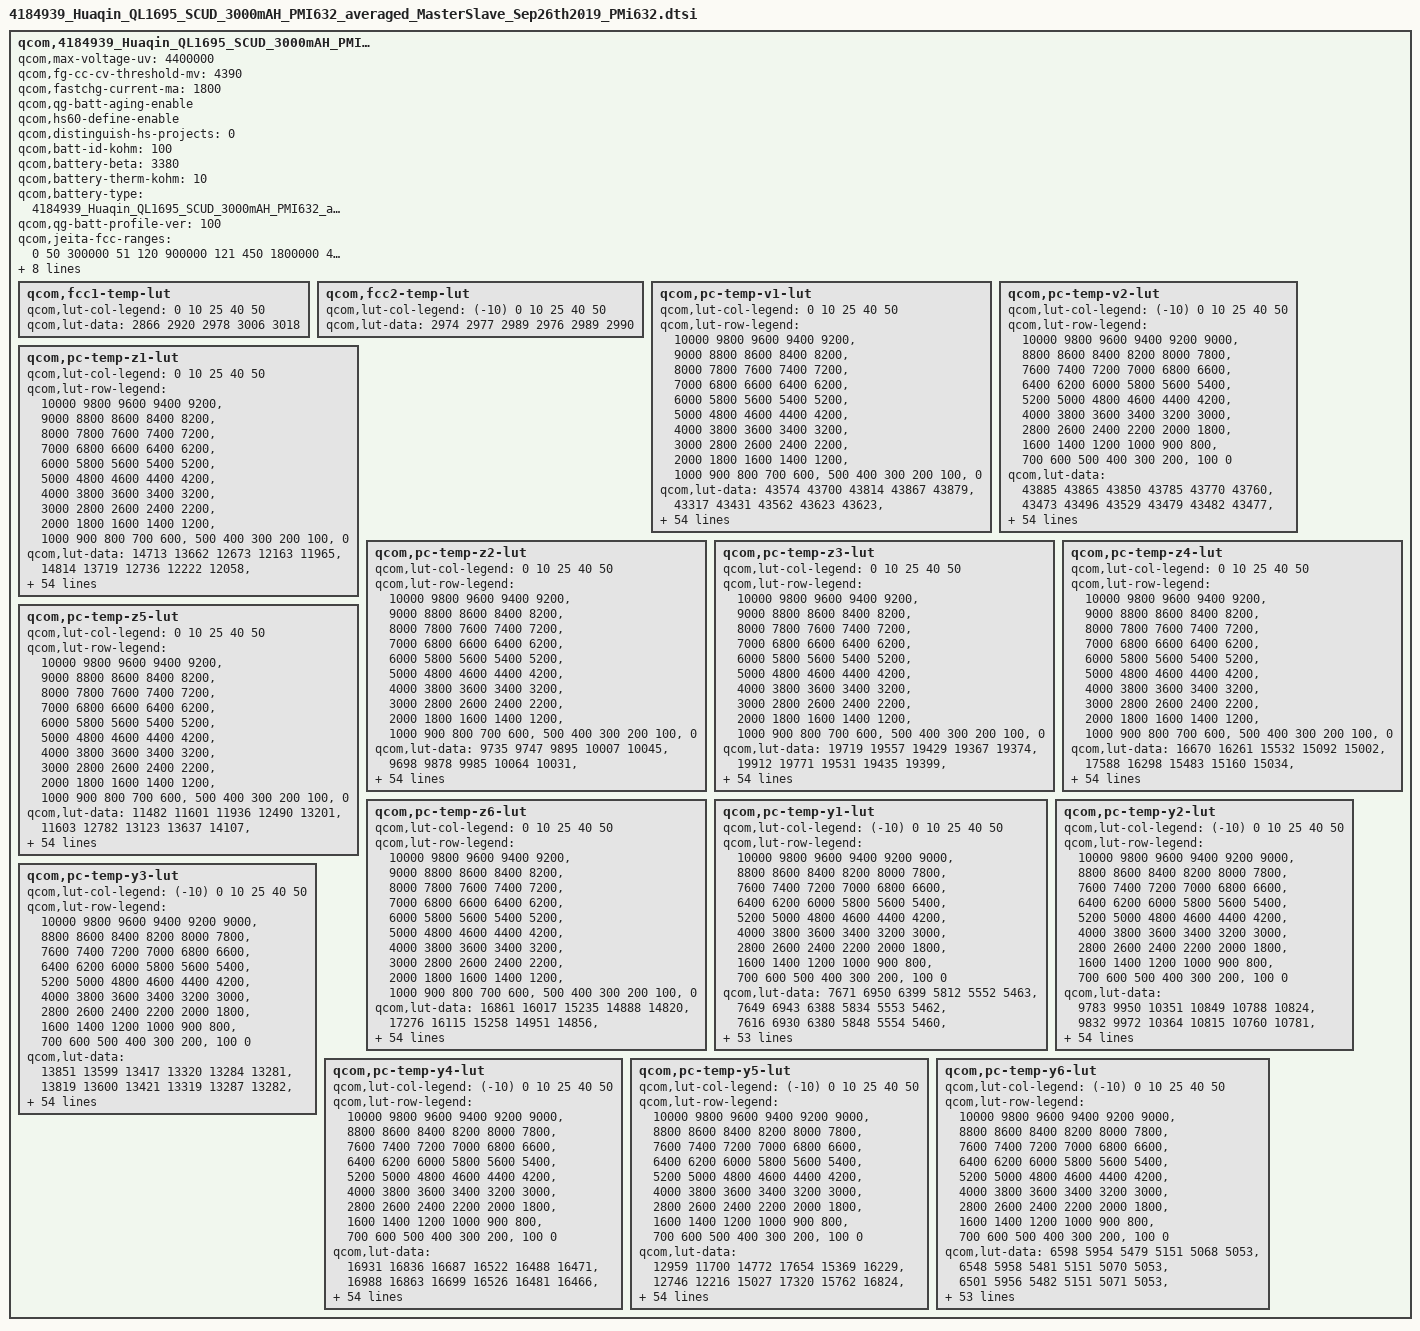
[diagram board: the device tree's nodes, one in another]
qcom,4184939_Huaqin_QL1695_SCUD_3000mAH_PMI632 {
    /* 4184939_Huaqin_QL1695_SCUD_3000mAH_PMI632_averaged_MasterSlave_Sep26th2019 */
    qcom,max-voltage-uv = <4400000>;
    qcom,fg-cc-cv-threshold-mv = <4390>;
    /* HS60 add for ZQL1693-60 Encrease FCC to 1800mA to trigger TA(5V/1.55A) more ICL by gaochao at 2019/11/05 start */
    qcom,fastchg-current-ma = <1800>;
    /* HS60 add for ZQL1693-60 Encrease FCC to 1800mA to trigger TA(5V/1.55A) more ICL by gaochao at 2019/11/05 end */
	/* HS60 add for SR-ZQL1695-01-357 Import battery aging by gaochao at 2019/08/29 start */
	qcom,qg-batt-aging-enable;
	/* HS60 add for SR-ZQL1695-01-357 Import battery aging by gaochao at 2019/08/29 end */
    /* HS70 add for HS70-135 Distinguish HS60 and HS70 charging by gaochao at 2019/10/03 start */
    qcom,hs60-define-enable;
    /* HS70 add for HS70-135 Distinguish HS60 and HS70 charging by gaochao at 2019/10/03 end */
	/* HS50 add for SR-QL3095-01-67 Distinguish HS60, HS70 and HS50 charging by wenyaqi at 2020/8/3 start */
	qcom,distinguish-hs-projects = <0>;
	/* HS50 add for SR-QL3095-01-67 Distinguish HS60, HS70 and HS50 charging by wenyaqi at 2020/8/3 end */
    qcom,batt-id-kohm = <100>;
    qcom,battery-beta = <3380>;
    qcom,battery-therm-kohm = <10>;
    qcom,battery-type = "4184939_Huaqin_QL1695_SCUD_3000mAH_PMI632_averaged_MasterSlave_Sep26th2019";
    qcom,qg-batt-profile-ver = <100>;

	/*HS60 add for ZQL1693-50 by wangzikang at 2019/09/26 start*/
	/*HS60 add for ZQL1693-58 by wangzikang at 2019/10/18 start*/
	/* HS60 add for ZQL1693-60 Encrease FCC to 1800mA to trigger TA(5V/1.55A) more ICL by gaochao at 2019/11/05 start */
	qcom,jeita-fcc-ranges = <0   50   300000
				 51   120   900000
				 121 450  1800000
				 451 500  1800000>;
	/* HS60 add for ZQL1693-60 Encrease FCC to 1800mA to trigger TA(5V/1.55A) more ICL by gaochao at 2019/11/05 end */
	/*HS60 add for ZQL1693-58 by wangzikang at 2019/10/18 end*/
	qcom,jeita-fv-ranges =  <0   50  4400000
				 51   120  4400000
				 121 450  4400000
				 451 500  4200000>;
	/*HS60 add for ZQL1693-50 by wangzikang at 2019/09/26 end*/

	/* HS60 add for SR-ZQL1695-01-357 Import battery aging by gaochao at 2019/08/29 start */
	qcom,vfloat-ranges = <0 299 4400000
	                      300 399 4380000
                              400 699 4360000
                              700 999 4340000
                              1000 9999 4290000>;

	qcom,vbat-rechg-ranges = <0 299 4330000
                                  300 399 4310000
                                  400 699 4290000
                                  700 999 4270000
                                  1000 9999 4220000>;
	/* HS60 add for SR-ZQL1695-01-357 Import battery aging by gaochao at 2019/08/29 end */

	/* COOL = 15 DegC, WARM = 45 DegC */
	qcom,jeita-soft-thresholds = <0x2554 0xFDC>;
	/* COLD = 0 DegC, HOT = 55 DegC */
	/*HS60 add for USER REQUEIREMENT by wangzikang at 2019/09/26 start*/
	qcom,jeita-hard-thresholds = <0x36B9 0xDBF>;//0xBEF -->0xDBF
	/*HS60 add for USER REQUEIREMENT by wangzikang at 2019/09/26 end*/

	qcom,fcc1-temp-lut {
		qcom,lut-col-legend = <0 10 25 40 50>;
		qcom,lut-data = <2866 2920 2978 3006 3018>;
	};

	qcom,fcc2-temp-lut {
		qcom,lut-col-legend = <(-10) 0 10 25 40 50>;
		qcom,lut-data = <2974 2977 2989 2976 2989 2990>;
	};

	qcom,pc-temp-v1-lut {
		qcom,lut-col-legend = <0 10 25 40 50>;
		qcom,lut-row-legend = <10000 9800 9600 9400 9200>,
			<9000 8800 8600 8400 8200>,
			<8000 7800 7600 7400 7200>,
			<7000 6800 6600 6400 6200>,
			<6000 5800 5600 5400 5200>,
			<5000 4800 4600 4400 4200>,
			<4000 3800 3600 3400 3200>,
			<3000 2800 2600 2400 2200>,
			<2000 1800 1600 1400 1200>,
			<1000 900 800 700 600>,
			<500 400 300 200 100>,
			<0>;
		qcom,lut-data = <43574 43700 43814 43867 43879>,
			<43317 43431 43562 43623 43623>,
			<43056 43180 43314 43377 43379>,
			<42805 42941 43072 43135 43142>,
			<42568 42706 42833 42898 42910>,
			<42340 42471 42595 42661 42679>,
			<42114 42239 42359 42428 42447>,
			<41891 42010 42125 42196 42213>,
			<41675 41785 41896 41966 41982>,
			<41468 41566 41669 41735 41755>,
			<41268 41356 41447 41507 41529>,
			<41068 41153 41231 41287 41307>,
			<40870 40953 41019 41070 41088>,
			<40669 40761 40815 40862 40877>,
			<40449 40565 40614 40658 40672>,
			<40207 40350 40421 40462 40475>,
			<40001 40132 40230 40274 40284>,
			<39853 39956 40049 40093 40102>,
			<39728 39820 39886 39922 39928>,
			<39602 39690 39738 39769 39772>,
			<39474 39550 39581 39607 39608>,
			<39348 39404 39416 39403 39401>,
			<39225 39240 39238 39173 39165>,
			<39103 39029 39020 38976 38970>,
			<38983 38819 38766 38805 38814>,
			<38865 38666 38600 38664 38683>,
			<38749 38537 38523 38561 38574>,
			<38636 38445 38464 38476 38480>,
			<38520 38382 38402 38394 38390>,
			<38426 38335 38341 38313 38300>,
			<38364 38294 38284 38238 38218>,
			<38314 38261 38227 38169 38147>,
			<38275 38229 38173 38107 38084>,
			<38244 38198 38124 38052 38026>,
			<38217 38168 38081 38005 37974>,
			<38188 38137 38041 37960 37923>,
			<38160 38108 38006 37913 37867>,
			<38123 38071 37968 37865 37808>,
			<38071 38012 37908 37801 37735>,
			<38000 37924 37816 37715 37647>,
			<37909 37824 37712 37615 37547>,
			<37778 37706 37603 37504 37435>,
			<37631 37567 37475 37377 37306>,
			<37466 37395 37308 37216 37145>,
			<37317 37251 37158 37070 37002>,
			<37223 37155 37062 36976 36914>,
			<37191 37130 37039 36952 36894>,
			<37161 37104 37019 36938 36878>,
			<37136 37080 37006 36919 36859>,
			<37092 37037 36961 36871 36803>,
			<36898 36828 36741 36624 36526>,
			<36445 36384 36307 36180 36085>,
			<35868 35808 35734 35603 35506>,
			<35084 35020 34952 34816 34714>,
			<33838 33777 33735 33556 33483>,
			<30000 30000 30000 30000 30000>;
	};

	qcom,pc-temp-v2-lut {
		qcom,lut-col-legend = <(-10) 0 10 25 40 50>;
		qcom,lut-row-legend = <10000 9800 9600 9400 9200 9000>,
			<8800 8600 8400 8200 8000 7800>,
			<7600 7400 7200 7000 6800 6600>,
			<6400 6200 6000 5800 5600 5400>,
			<5200 5000 4800 4600 4400 4200>,
			<4000 3800 3600 3400 3200 3000>,
			<2800 2600 2400 2200 2000 1800>,
			<1600 1400 1200 1000 900 800>,
			<700 600 500 400 300 200>,
			<100 0>;
		qcom,lut-data = <43885 43865 43850 43785 43770 43760>,
			<43473 43496 43529 43479 43482 43477>,
			<43106 43162 43231 43193 43211 43209>,
			<42794 42870 42957 42931 42956 42957>,
			<42525 42615 42708 42690 42719 42721>,
			<42282 42372 42466 42456 42487 42490>,
			<42064 42124 42224 42222 42254 42257>,
			<41859 41882 41986 41991 42022 42026>,
			<41624 41647 41756 41764 41794 41798>,
			<41341 41412 41531 41540 41568 41573>,
			<41103 41198 41313 41320 41346 41350>,
			<40973 41030 41106 41107 41130 41132>,
			<40870 40878 40907 40897 40917 40918>,
			<40674 40681 40714 40692 40712 40712>,
			<40245 40416 40529 40486 40509 40512>,
			<39841 40143 40334 40290 40315 40320>,
			<39631 39895 40108 40115 40130 40133>,
			<39473 39658 39868 39950 39952 39953>,
			<39312 39452 39647 39784 39785 39783>,
			<39150 39274 39439 39620 39635 39627>,
			<38988 39107 39242 39443 39469 39458>,
			<38816 38943 39052 39220 39248 39244>,
			<38642 38785 38873 38974 39003 39013>,
			<38495 38628 38714 38780 38810 38824>,
			<38373 38464 38573 38633 38654 38666>,
			<38268 38318 38447 38507 38522 38530>,
			<38184 38207 38335 38393 38411 38417>,
			<38113 38113 38233 38292 38315 38319>,
			<38048 38043 38131 38200 38226 38228>,
			<37988 37989 38024 38117 38145 38145>,
			<37931 37944 37940 38042 38070 38069>,
			<37872 37899 37887 37973 37999 38000>,
			<37813 37857 37847 37912 37933 37936>,
			<37753 37814 37809 37855 37867 37868>,
			<37692 37770 37777 37804 37803 37801>,
			<37631 37724 37743 37754 37734 37725>,
			<37570 37674 37706 37697 37651 37626>,
			<37509 37620 37666 37635 37559 37513>,
			<37448 37559 37614 37568 37474 37417>,
			<37388 37490 37546 37497 37397 37338>,
			<37329 37411 37462 37416 37316 37256>,
			<37272 37313 37349 37317 37218 37159>,
			<37216 37198 37214 37195 37105 37048>,
			<37153 37095 37074 37051 36966 36911>,
			<37083 37002 36948 36919 36852 36804>,
			<36987 36916 36863 36852 36801 36757>,
			<36924 36877 36832 36837 36789 36744>,
			<36859 36837 36803 36818 36773 36729>,
			<36780 36796 36761 36791 36744 36700>,
			<36666 36720 36683 36725 36654 36598>,
			<36461 36516 36472 36494 36341 36271>,
			<36082 36089 36032 36027 35843 35770>,
			<35495 35465 35405 35417 35201 35119>,
			<34623 34590 34539 34597 34325 34250>,
			<33196 33262 33270 33322 32996 32924>,
			<28548 27862 27939 28567 27880 28103>;
	};

	qcom,pc-temp-z1-lut {
		qcom,lut-col-legend = <0 10 25 40 50>;
		qcom,lut-row-legend = <10000 9800 9600 9400 9200>,
			<9000 8800 8600 8400 8200>,
			<8000 7800 7600 7400 7200>,
			<7000 6800 6600 6400 6200>,
			<6000 5800 5600 5400 5200>,
			<5000 4800 4600 4400 4200>,
			<4000 3800 3600 3400 3200>,
			<3000 2800 2600 2400 2200>,
			<2000 1800 1600 1400 1200>,
			<1000 900 800 700 600>,
			<500 400 300 200 100>,
			<0>;
		qcom,lut-data = <14713 13662 12673 12163 11965>,
			<14814 13719 12736 12222 12058>,
			<14837 13710 12765 12244 12079>,
			<14842 13676 12757 12242 12081>,
			<14832 13653 12747 12235 12080>,
			<14812 13641 12735 12228 12078>,
			<14796 13632 12717 12223 12077>,
			<14778 13621 12698 12219 12077>,
			<14766 13599 12683 12216 12077>,
			<14754 13587 12671 12214 12075>,
			<14731 13593 12667 12212 12074>,
			<14710 13602 12670 12212 12075>,
			<14666 13595 12672 12211 12075>,
			<14612 13547 12670 12210 12076>,
			<14580 13511 12663 12210 12077>,
			<14554 13507 12660 12210 12078>,
			<14526 13505 12662 12211 12079>,
			<14480 13506 12666 12213 12080>,
			<14434 13519 12671 12215 12080>,
			<14423 13529 12679 12217 12082>,
			<14431 13530 12684 12220 12084>,
			<14446 13531 12688 12221 12085>,
			<14477 13535 12692 12223 12086>,
			<14530 13545 12695 12225 12088>,
			<14553 13555 12699 12227 12091>,
			<14524 13554 12704 12230 12094>,
			<14486 13551 12712 12235 12098>,
			<14483 13549 12719 12242 12103>,
			<14501 13557 12724 12247 12108>,
			<14517 13568 12727 12252 12113>,
			<14524 13574 12732 12257 12118>,
			<14530 13577 12741 12263 12122>,
			<14534 13581 12752 12269 12126>,
			<14527 13598 12760 12275 12130>,
			<14520 13625 12765 12282 12135>,
			<14528 13642 12771 12288 12139>,
			<14549 13652 12778 12292 12143>,
			<14563 13662 12786 12297 12146>,
			<14580 13674 12793 12302 12150>,
			<14600 13687 12801 12308 12154>,
			<14602 13695 12809 12314 12158>,
			<14594 13701 12825 12320 12162>,
			<14599 13702 12836 12326 12166>,
			<14627 13688 12838 12331 12170>,
			<14896 13713 12859 12338 12174>,
			<14641 13727 12865 12344 12176>,
			<14631 13714 12861 12346 12177>,
			<14608 13728 12858 12346 12179>,
			<14659 13689 12864 12348 12182>,
			<14623 13745 12882 12356 12185>,
			<14644 13777 12879 12365 12193>,
			<14726 13752 12908 12375 12203>,
			<14712 13783 12914 12395 12217>,
			<14712 13859 12978 12417 12236>,
			<14712 13859 12978 12417 12236>,
			<14712 13859 12978 12417 12236>;
	};

	qcom,pc-temp-z2-lut {
		qcom,lut-col-legend = <0 10 25 40 50>;
		qcom,lut-row-legend = <10000 9800 9600 9400 9200>,
			<9000 8800 8600 8400 8200>,
			<8000 7800 7600 7400 7200>,
			<7000 6800 6600 6400 6200>,
			<6000 5800 5600 5400 5200>,
			<5000 4800 4600 4400 4200>,
			<4000 3800 3600 3400 3200>,
			<3000 2800 2600 2400 2200>,
			<2000 1800 1600 1400 1200>,
			<1000 900 800 700 600>,
			<500 400 300 200 100>,
			<0>;
		qcom,lut-data = <9735 9747 9895 10007 10045>,
			<9698 9878 9985 10064 10031>,
			<9781 9879 10030 10125 10123>,
			<9834 9855 10018 10139 10165>,
			<9846 9834 9984 10113 10116>,
			<9853 9819 9955 10078 10057>,
			<9853 9808 9931 10045 10044>,
			<9845 9806 9913 10010 10040>,
			<9837 9805 9908 10001 10032>,
			<9831 9805 9907 10017 9990>,
			<9825 9798 9908 10031 9942>,
			<9818 9790 9919 10029 9924>,
			<9803 9788 9933 10021 9912>,
			<9786 9791 9943 10014 9914>,
			<9772 9794 9953 10006 9935>,
			<9758 9797 9963 10000 9958>,
			<9751 9802 9974 9994 9968>,
			<9755 9810 9984 9987 9976>,
			<9762 9828 9990 9990 9984>,
			<9763 9848 9996 9996 9998>,
			<9753 9862 10004 10006 10021>,
			<9743 9874 10024 10081 10103>,
			<9740 9885 10042 10217 10247>,
			<9738 9898 10041 10241 10281>,
			<9738 9907 10029 10100 10145>,
			<9742 9906 10018 9981 10025>,
			<9751 9901 10006 9993 10048>,
			<9759 9898 9997 10032 10110>,
			<9771 9903 10007 10075 10138>,
			<9780 9910 10045 10134 10144>,
			<9784 9913 10068 10173 10143>,
			<9787 9915 10072 10158 10086>,
			<9790 9917 10073 10124 9980>,
			<9795 9920 10072 10107 9951>,
			<9801 9925 10068 10099 9957>,
			<9808 9930 10068 10095 9968>,
			<9817 9933 10073 10102 10000>,
			<9827 9938 10081 10119 10056>,
			<9840 9947 10093 10140 10094>,
			<9854 9960 10116 10169 10123>,
			<9865 9967 10131 10187 10140>,
			<9875 9969 10135 10181 10143>,
			<9889 9971 10138 10172 10143>,
			<9916 9982 10139 10177 10147>,
			<10099 10081 10176 10170 10151>,
			<10227 10116 10181 10155 10111>,
			<10267 10148 10181 10137 10148>,
			<10264 10169 10168 10166 10136>,
			<10112 10217 10173 10179 10142>,
			<9839 10250 10189 10237 10292>,
			<9856 10244 10308 10258 10078>,
			<10139 10252 10344 10151 9981>,
			<9997 10225 10324 10074 9930>,
			<9839 10155 10292 10002 9887>,
			<9839 10155 10292 10002 9887>,
			<9839 10155 10292 10002 9887>;
	};

	qcom,pc-temp-z3-lut {
		qcom,lut-col-legend = <0 10 25 40 50>;
		qcom,lut-row-legend = <10000 9800 9600 9400 9200>,
			<9000 8800 8600 8400 8200>,
			<8000 7800 7600 7400 7200>,
			<7000 6800 6600 6400 6200>,
			<6000 5800 5600 5400 5200>,
			<5000 4800 4600 4400 4200>,
			<4000 3800 3600 3400 3200>,
			<3000 2800 2600 2400 2200>,
			<2000 1800 1600 1400 1200>,
			<1000 900 800 700 600>,
			<500 400 300 200 100>,
			<0>;
		qcom,lut-data = <19719 19557 19429 19367 19374>,
			<19912 19771 19531 19435 19399>,
			<20028 19829 19593 19467 19433>,
			<20069 19859 19611 19485 19451>,
			<19993 19866 19621 19500 19455>,
			<19881 19862 19625 19508 19457>,
			<19851 19856 19624 19504 19457>,
			<19846 19851 19620 19494 19453>,
			<19845 19848 19610 19485 19447>,
			<19848 19844 19592 19478 19435>,
			<19856 19832 19576 19470 19422>,
			<19862 19813 19562 19459 19414>,
			<19864 19790 19550 19445 19409>,
			<19866 19757 19542 19434 19404>,
			<19877 19730 19534 19424 19397>,
			<19902 19717 19527 19416 19390>,
			<19918 19708 19517 19410 19385>,
			<19904 19695 19508 19402 19380>,
			<19880 19672 19500 19398 19376>,
			<19875 19656 19493 19394 19371>,
			<19886 19657 19491 19390 19369>,
			<19898 19663 19499 19401 19375>,
			<19905 19672 19508 19425 19392>,
			<19915 19693 19511 19430 19395>,
			<19922 19711 19513 19409 19368>,
			<19929 19712 19512 19388 19344>,
			<19935 19709 19501 19380 19344>,
			<19940 19704 19488 19375 19345>,
			<19943 19700 19487 19377 19352>,
			<19945 19695 19489 19399 19389>,
			<19939 19689 19492 19423 19420>,
			<19924 19681 19505 19433 19418>,
			<19908 19675 19520 19440 19409>,
			<19892 19671 19521 19441 19400>,
			<19874 19668 19517 19430 19391>,
			<19854 19664 19512 19418 19383>,
			<19833 19658 19504 19410 19377>,
			<19814 19652 19495 19404 19372>,
			<19797 19647 19490 19398 19368>,
			<19782 19642 19487 19393 19364>,
			<19772 19636 19484 19390 19362>,
			<19766 19627 19477 19389 19363>,
			<19757 19617 19470 19389 19363>,
			<19741 19609 19466 19387 19361>,
			<19645 19559 19451 19379 19361>,
			<19476 19531 19441 19374 19360>,
			<19365 19497 19432 19373 19349>,
			<19351 19486 19434 19362 19349>,
			<19311 19465 19397 19361 19343>,
			<19268 19460 19409 19350 19327>,
			<19281 19468 19374 19351 19370>,
			<19363 19444 19360 19369 19376>,
			<19366 19390 19360 19371 19379>,
			<19373 19376 19355 19382 19381>,
			<19373 19376 19355 19382 19381>,
			<19373 19376 19355 19382 19381>;
	};

	qcom,pc-temp-z4-lut {
		qcom,lut-col-legend = <0 10 25 40 50>;
		qcom,lut-row-legend = <10000 9800 9600 9400 9200>,
			<9000 8800 8600 8400 8200>,
			<8000 7800 7600 7400 7200>,
			<7000 6800 6600 6400 6200>,
			<6000 5800 5600 5400 5200>,
			<5000 4800 4600 4400 4200>,
			<4000 3800 3600 3400 3200>,
			<3000 2800 2600 2400 2200>,
			<2000 1800 1600 1400 1200>,
			<1000 900 800 700 600>,
			<500 400 300 200 100>,
			<0>;
		qcom,lut-data = <16670 16261 15532 15092 15002>,
			<17588 16298 15483 15160 15034>,
			<17274 16176 15414 15103 14998>,
			<16961 15837 15313 15045 14959>,
			<16726 15574 15181 14985 14921>,
			<16506 15416 15083 14930 14883>,
			<16301 15290 15012 14890 14848>,
			<16106 15184 14956 14859 14814>,
			<15935 15093 14910 14833 14797>,
			<15797 15025 14870 14810 14791>,
			<15679 14978 14845 14793 14786>,
			<15570 14940 14833 14784 14778>,
			<15464 14905 14822 14777 14767>,
			<15370 14869 14808 14769 14756>,
			<15296 14848 14791 14758 14745>,
			<15235 14846 14778 14748 14734>,
			<15178 14845 14768 14740 14724>,
			<15120 14841 14759 14729 14713>,
			<15066 14823 14748 14719 14704>,
			<15017 14802 14735 14707 14692>,
			<14973 14786 14731 14699 14685>,
			<14936 14771 14737 14718 14707>,
			<14907 14768 14750 14771 14772>,
			<14880 14818 14802 14825 14829>,
			<14866 14884 14927 14890 14883>,
			<14858 14920 14982 14931 14916>,
			<14853 14949 14968 14926 14910>,
			<14856 14960 14944 14909 14886>,
			<14874 14945 14919 14884 14854>,
			<14887 14919 14889 14839 14792>,
			<14886 14895 14859 14793 14741>,
			<14881 14871 14824 14759 14725>,
			<14875 14849 14793 14732 14714>,
			<14865 14829 14778 14724 14710>,
			<14853 14810 14769 14722 14708>,
			<14843 14795 14762 14721 14707>,
			<14835 14779 14758 14724 14711>,
			<14827 14770 14755 14731 14721>,
			<14818 14771 14759 14741 14733>,
			<14810 14774 14776 14759 14748>,
			<14805 14774 14786 14770 14757>,
			<14800 14768 14773 14760 14748>,
			<14793 14761 14759 14746 14736>,
			<14779 14759 14756 14750 14743>,
			<14767 14737 14736 14745 14733>,
			<14904 14726 14713 14718 14709>,
			<15023 14743 14700 14703 14701>,
			<15031 14741 14679 14686 14674>,
			<15063 14753 14697 14658 14653>,
			<15096 14751 14679 14666 14664>,
			<15074 14753 14750 14711 14668>,
			<15021 14805 14781 14701 14668>,
			<15044 14878 14784 14701 14668>,
			<15063 14910 14794 14692 14667>,
			<15063 14910 14794 14692 14667>,
			<15063 14910 14794 14692 14667>;
	};

	qcom,pc-temp-z5-lut {
		qcom,lut-col-legend = <0 10 25 40 50>;
		qcom,lut-row-legend = <10000 9800 9600 9400 9200>,
			<9000 8800 8600 8400 8200>,
			<8000 7800 7600 7400 7200>,
			<7000 6800 6600 6400 6200>,
			<6000 5800 5600 5400 5200>,
			<5000 4800 4600 4400 4200>,
			<4000 3800 3600 3400 3200>,
			<3000 2800 2600 2400 2200>,
			<2000 1800 1600 1400 1200>,
			<1000 900 800 700 600>,
			<500 400 300 200 100>,
			<0>;
		qcom,lut-data = <11482 11601 11936 12490 13201>,
			<11603 12782 13123 13637 14107>,
			<12083 13270 13983 14569 15450>,
			<12344 13551 14465 15252 16156>,
			<12313 13818 14819 15887 16321>,
			<12269 14066 15179 16311 16447>,
			<12281 14338 15621 16370 16792>,
			<12440 14805 15999 16349 17364>,
			<12638 15534 16340 16451 17553>,
			<12795 16161 16792 17073 17100>,
			<12949 16604 17022 17601 16614>,
			<13071 16966 17060 17456 16648>,
			<13154 17220 17092 17086 16907>,
			<13245 17402 17410 16936 17106>,
			<13488 17571 18126 17120 17193>,
			<14032 17771 18584 17243 17294>,
			<14423 17969 18753 17216 17579>,
			<14511 18085 18927 17431 18167>,
			<14570 18154 19362 17908 18889>,
			<14748 18271 20347 18624 19767>,
			<15444 19260 21882 19791 21098>,
			<16430 22179 25979 25754 25202>,
			<17561 26245 30121 36012 31939>,
			<19142 35073 30983 37916 33257>,
			<21050 42976 30889 28403 24505>,
			<23601 42717 30138 19276 16079>,
			<26591 38746 26128 16764 14620>,
			<29763 35084 21500 15285 13892>,
			<33591 32612 20056 15065 13981>,
			<35741 30525 19321 15960 16510>,
			<34831 28924 19127 17457 19412>,
			<32602 27495 21086 20404 20942>,
			<30486 26820 24326 24504 22117>,
			<28293 27157 27038 26488 23097>,
			<26124 27885 29799 27450 24110>,
			<24255 28479 30961 27885 24674>,
			<22497 28969 30618 27387 24284>,
			<21515 29428 29959 26043 23218>,
			<21082 29981 29133 24380 21869>,
			<20772 30594 27687 21772 19684>,
			<20821 30620 26124 19855 18081>,
			<21527 28221 24420 19461 17727>,
			<22369 26711 23087 19177 17463>,
			<23296 26557 22336 18291 16828>,
			<21405 24508 22548 17843 17125>,
			<13528 22147 22944 18147 17509>,
			<11534 17091 21612 18585 16593>,
			<11390 16338 23324 18182 18076>,
			<11087 15109 16663 20755 20447>,
			<10853 14957 19044 18471 16501>,
			<11013 15778 14133 14579 18569>,
			<11560 13839 12865 15039 18340>,
			<11424 12203 12658 14839 17911>,
			<11333 11774 12315 15389 17418>,
			<11333 11774 12315 15389 17418>,
			<11333 11774 12315 15389 17418>;
	};

	qcom,pc-temp-z6-lut {
		qcom,lut-col-legend = <0 10 25 40 50>;
		qcom,lut-row-legend = <10000 9800 9600 9400 9200>,
			<9000 8800 8600 8400 8200>,
			<8000 7800 7600 7400 7200>,
			<7000 6800 6600 6400 6200>,
			<6000 5800 5600 5400 5200>,
			<5000 4800 4600 4400 4200>,
			<4000 3800 3600 3400 3200>,
			<3000 2800 2600 2400 2200>,
			<2000 1800 1600 1400 1200>,
			<1000 900 800 700 600>,
			<500 400 300 200 100>,
			<0>;
		qcom,lut-data = <16861 16017 15235 14888 14820>,
			<17276 16115 15258 14951 14856>,
			<17145 16065 15265 14951 14862>,
			<16990 15907 15241 14945 14862>,
			<16810 15773 15179 14926 14851>,
			<16617 15683 15130 14904 14833>,
			<16473 15606 15095 14884 14817>,
			<16361 15543 15064 14865 14802>,
			<16268 15489 15034 14849 14790>,
			<16195 15445 15005 14835 14780>,
			<16135 15411 14986 14822 14771>,
			<16072 15381 14974 14811 14763>,
			<16001 15346 14963 14801 14755>,
			<15936 15302 14951 14791 14747>,
			<15894 15271 14938 14781 14738>,
			<15863 15262 14926 14772 14730>,
			<15834 15256 14917 14763 14722>,
			<15795 15246 14908 14755 14715>,
			<15758 15229 14900 14748 14708>,
			<15740 15217 14892 14740 14700>,
			<15731 15215 14890 14736 14696>,
			<15726 15215 14896 14750 14710>,
			<15722 15216 14908 14786 14749>,
			<15720 15249 14936 14811 14770>,
			<15719 15290 14990 14827 14780>,
			<15721 15309 15014 14836 14784>,
			<15725 15321 15004 14832 14781>,
			<15732 15325 14989 14822 14773>,
			<15743 15319 14978 14814 14766>,
			<15750 15306 14967 14808 14760>,
			<15748 15295 14959 14801 14755>,
			<15741 15283 14954 14795 14747>,
			<15734 15272 14949 14789 14739>,
			<15725 15265 14944 14782 14732>,
			<15714 15259 14940 14776 14725>,
			<15703 15254 14936 14771 14722>,
			<15692 15248 14931 14770 14722>,
			<15685 15245 14927 14769 14723>,
			<15682 15247 14928 14770 14725>,
			<15680 15253 14937 14776 14730>,
			<15680 15254 14941 14780 14733>,
			<15684 15252 14935 14776 14730>,
			<15686 15251 14929 14771 14726>,
			<15681 15253 14928 14772 14728>,
			<15638 15230 14917 14767 14725>,
			<15619 15216 14904 14754 14714>,
			<15613 15208 14895 14747 14705>,
			<15608 15203 14887 14734 14694>,
			<15606 15200 14878 14722 14681>,
			<15608 15203 14880 14721 14678>,
			<15617 15217 14897 14743 14704>,
			<15646 15238 14908 14751 14711>,
			<15676 15257 14917 14756 14715>,
			<15720 15287 14928 14763 14721>,
			<15720 15287 14928 14763 14721>,
			<15720 15287 14928 14763 14721>;
	};

	qcom,pc-temp-y1-lut {
		qcom,lut-col-legend = <(-10) 0 10 25 40 50>;
		qcom,lut-row-legend = <10000 9800 9600 9400 9200 9000>,
			<8800 8600 8400 8200 8000 7800>,
			<7600 7400 7200 7000 6800 6600>,
			<6400 6200 6000 5800 5600 5400>,
			<5200 5000 4800 4600 4400 4200>,
			<4000 3800 3600 3400 3200 3000>,
			<2800 2600 2400 2200 2000 1800>,
			<1600 1400 1200 1000 900 800>,
			<700 600 500 400 300 200>,
			<100 0>;
		qcom,lut-data = <7671 6950 6399 5812 5552 5463>,
			<7649 6943 6388 5834 5553 5462>,
			<7616 6930 6380 5848 5554 5460>,
			<7580 6913 6375 5855 5554 5459>,
			<7550 6898 6372 5858 5554 5458>,
			<7534 6889 6371 5858 5554 5457>,
			<7529 6881 6379 5852 5553 5456>,
			<7527 6872 6393 5841 5550 5454>,
			<7528 6866 6395 5836 5548 5453>,
			<7542 6869 6390 5833 5545 5452>,
			<7553 6873 6384 5832 5543 5451>,
			<7549 6876 6378 5831 5541 5450>,
			<7538 6881 6373 5829 5540 5450>,
			<7534 6886 6370 5828 5538 5449>,
			<7526 6892 6367 5823 5535 5449>,
			<7521 6896 6366 5820 5534 5448>,
			<7551 6888 6378 5822 5534 5449>,
			<7611 6870 6397 5826 5535 5449>,
			<7625 6865 6400 5828 5535 5449>,
			<7602 6862 6392 5829 5535 5450>,
			<7581 6860 6386 5830 5535 5450>,
			<7577 6862 6397 5833 5536 5451>,
			<7575 6865 6415 5838 5538 5451>,
			<7573 6864 6416 5843 5540 5452>,
			<7566 6851 6395 5848 5542 5454>,
			<7556 6840 6379 5853 5544 5456>,
			<7543 6845 6388 5855 5547 5458>,
			<7527 6858 6406 5857 5550 5461>,
			<7519 6866 6416 5860 5553 5463>,
			<7525 6865 6424 5866 5558 5466>,
			<7531 6861 6430 5874 5562 5469>,
			<7526 6853 6428 5884 5566 5472>,
			<7521 6837 6422 5896 5569 5476>,
			<7523 6827 6413 5900 5573 5479>,
			<7510 6832 6394 5898 5577 5481>,
			<7492 6841 6381 5896 5580 5483>,
			<7483 6842 6390 5900 5583 5484>,
			<7470 6842 6405 5913 5586 5486>,
			<7468 6843 6408 5925 5589 5488>,
			<7486 6834 6415 5935 5592 5490>,
			<7501 6822 6422 5944 5595 5493>,
			<7491 6821 6421 5953 5599 5495>,
			<7478 6828 6419 5963 5604 5498>,
			<7464 6833 6403 5966 5611 5502>,
			<7440 6835 6396 5977 5618 5506>,
			<7544 6845 6453 5982 5626 5514>,
			<7611 6920 6455 5982 5629 5515>,
			<7598 6878 6431 5987 5632 5516>,
			<7601 6870 6445 5989 5632 5516>,
			<7533 6881 6420 6008 5631 5516>,
			<7552 6866 6446 6016 5636 5520>,
			<7565 6884 6442 6028 5645 5527>,
			<7619 6901 6452 6075 5659 5537>,
			<7669 6982 6489 6090 5679 5549>,
			<7669 6982 6489 6090 5679 5549>,
			<7669 6982 6489 6090 5679 5549>;
	};

	qcom,pc-temp-y2-lut {
		qcom,lut-col-legend = <(-10) 0 10 25 40 50>;
		qcom,lut-row-legend = <10000 9800 9600 9400 9200 9000>,
			<8800 8600 8400 8200 8000 7800>,
			<7600 7400 7200 7000 6800 6600>,
			<6400 6200 6000 5800 5600 5400>,
			<5200 5000 4800 4600 4400 4200>,
			<4000 3800 3600 3400 3200 3000>,
			<2800 2600 2400 2200 2000 1800>,
			<1600 1400 1200 1000 900 800>,
			<700 600 500 400 300 200>,
			<100 0>;
		qcom,lut-data = <9783 9950 10351 10849 10788 10824>,
			<9832 9972 10364 10815 10760 10781>,
			<9881 10012 10377 10771 10725 10740>,
			<9931 10056 10389 10727 10690 10701>,
			<9981 10093 10401 10690 10663 10668>,
			<10032 10111 10410 10668 10650 10641>,
			<10079 10112 10418 10659 10652 10620>,
			<10128 10112 10424 10653 10657 10603>,
			<10198 10133 10422 10650 10659 10588>,
			<10311 10260 10406 10648 10662 10574>,
			<10388 10353 10394 10648 10667 10567>,
			<10400 10355 10441 10667 10680 10581>,
			<10407 10356 10527 10705 10705 10612>,
			<10419 10363 10569 10726 10734 10647>,
			<10440 10413 10589 10737 10776 10691>,
			<10465 10466 10606 10747 10830 10742>,
			<10497 10493 10627 10760 10926 10801>,
			<10530 10514 10645 10776 11036 10866>,
			<10539 10543 10652 10805 11066 10928>,
			<10535 10590 10650 10878 11067 10997>,
			<10528 10621 10650 10932 11061 11034>,
			<10321 10614 10658 10901 10998 10974>,
			<9875 10594 10671 10835 10888 10863>,
			<9711 10577 10681 10815 10835 10815>,
			<9692 10561 10696 10823 10806 10793>,
			<9684 10551 10706 10834 10794 10782>,
			<9681 10552 10690 10846 10835 10806>,
			<9679 10554 10661 10863 10912 10860>,
			<9677 10553 10655 10881 10938 10907>,
			<9675 10534 10671 10906 10939 10961>,
			<9673 10493 10683 10927 10942 10990>,
			<9671 10294 10680 10932 11000 10972>,
			<9669 9882 10671 10933 11091 10939>,
			<9667 9713 10661 10933 11110 10949>,
			<9666 9694 10646 10928 11076 11085>,
			<9665 9684 10627 10921 11032 11193>,
			<9664 9677 10607 10906 10987 11113>,
			<9663 9673 10584 10876 10938 10948>,
			<9662 9670 10556 10851 10907 10874>,
			<9661 9667 10525 10833 10886 10846>,
			<9661 9665 10473 10814 10873 10830>,
			<9661 9663 10214 10790 10867 10830>,
			<9660 9662 9853 10758 10860 10833>,
			<9659 9660 9729 10698 10830 10811>,
			<9659 9659 9682 10618 10756 10743>,
			<9658 9659 9681 10585 10694 10634>,
			<9658 9659 9677 10624 10720 10619>,
			<9657 9658 9670 10606 10750 10655>,
			<9657 9657 9667 10611 10755 10713>,
			<9656 9657 9664 10602 10767 10662>,
			<9656 9656 9662 10576 10706 10608>,
			<9655 9655 9660 10518 10670 10564>,
			<9654 9654 9657 10462 10637 10483>,
			<9651 9654 9655 10402 10579 10471>,
			<9651 9654 9655 10402 10579 10471>,
			<9651 9654 9655 10402 10579 10471>;
	};

	qcom,pc-temp-y3-lut {
		qcom,lut-col-legend = <(-10) 0 10 25 40 50>;
		qcom,lut-row-legend = <10000 9800 9600 9400 9200 9000>,
			<8800 8600 8400 8200 8000 7800>,
			<7600 7400 7200 7000 6800 6600>,
			<6400 6200 6000 5800 5600 5400>,
			<5200 5000 4800 4600 4400 4200>,
			<4000 3800 3600 3400 3200 3000>,
			<2800 2600 2400 2200 2000 1800>,
			<1600 1400 1200 1000 900 800>,
			<700 600 500 400 300 200>,
			<100 0>;
		qcom,lut-data = <13851 13599 13417 13320 13284 13281>,
			<13819 13600 13421 13319 13287 13282>,
			<13785 13600 13424 13319 13289 13284>,
			<13752 13600 13428 13320 13291 13286>,
			<13724 13600 13431 13322 13293 13288>,
			<13705 13599 13433 13323 13296 13289>,
			<13696 13591 13434 13326 13298 13291>,
			<13689 13577 13435 13329 13299 13293>,
			<13672 13572 13435 13330 13301 13295>,
			<13626 13571 13434 13332 13302 13296>,
			<13586 13570 13432 13333 13304 13298>,
			<13568 13539 13427 13333 13308 13299>,
			<13555 13487 13420 13334 13313 13300>,
			<13544 13475 13416 13333 13314 13302>,
			<13533 13485 13414 13327 13313 13307>,
			<13524 13493 13412 13323 13313 13310>,
			<13513 13484 13409 13324 13312 13309>,
			<13503 13464 13407 13327 13311 13307>,
			<13495 13449 13402 13330 13309 13304>,
			<13487 13438 13393 13332 13307 13299>,
			<13481 13429 13385 13334 13303 13294>,
			<13480 13420 13378 13330 13300 13291>,
			<13480 13412 13373 13321 13296 13289>,
			<13478 13407 13368 13316 13293 13287>,
			<13470 13404 13362 13314 13290 13285>,
			<13465 13400 13359 13313 13289 13284>,
			<13467 13390 13358 13312 13289 13285>,
			<13473 13374 13357 13311 13290 13285>,
			<13482 13369 13355 13310 13290 13285>,
			<13498 13371 13347 13310 13290 13285>,
			<13517 13375 13342 13310 13291 13286>,
			<13532 13385 13343 13311 13293 13285>,
			<13547 13403 13346 13311 13295 13284>,
			<13565 13421 13350 13312 13295 13284>,
			<13589 13437 13354 13313 13293 13286>,
			<13617 13454 13358 13315 13291 13288>,
			<13644 13470 13362 13314 13290 13287>,
			<13672 13487 13366 13313 13289 13284>,
			<13702 13507 13369 13312 13288 13284>,
			<13736 13532 13373 13313 13289 13285>,
			<13772 13560 13376 13315 13290 13286>,
			<13814 13586 13379 13315 13290 13287>,
			<13861 13612 13382 13315 13290 13287>,
			<13910 13643 13405 13316 13289 13286>,
			<13959 13681 13435 13317 13289 13286>,
			<13977 13699 13440 13320 13294 13293>,
			<13927 13681 13442 13322 13298 13295>,
			<13995 13727 13462 13325 13304 13298>,
			<14058 13776 13489 13333 13309 13302>,
			<14131 13825 13523 13339 13311 13300>,
			<14208 13865 13549 13338 13301 13294>,
			<14298 13921 13592 13337 13304 13295>,
			<14462 14029 13691 13348 13311 13300>,
			<15012 14170 13811 13360 13317 13307>,
			<15012 14170 13811 13360 13317 13307>,
			<15012 14170 13811 13360 13317 13307>;
	};

	qcom,pc-temp-y4-lut {
		qcom,lut-col-legend = <(-10) 0 10 25 40 50>;
		qcom,lut-row-legend = <10000 9800 9600 9400 9200 9000>,
			<8800 8600 8400 8200 8000 7800>,
			<7600 7400 7200 7000 6800 6600>,
			<6400 6200 6000 5800 5600 5400>,
			<5200 5000 4800 4600 4400 4200>,
			<4000 3800 3600 3400 3200 3000>,
			<2800 2600 2400 2200 2000 1800>,
			<1600 1400 1200 1000 900 800>,
			<700 600 500 400 300 200>,
			<100 0>;
		qcom,lut-data = <16931 16836 16687 16522 16488 16471>,
			<16988 16863 16699 16526 16481 16466>,
			<17031 16896 16723 16529 16477 16463>,
			<17060 16929 16752 16532 16475 16460>,
			<17078 16957 16775 16535 16474 16458>,
			<17084 16973 16785 16538 16474 16458>,
			<17070 16981 16785 16539 16475 16458>,
			<17048 16986 16784 16541 16478 16460>,
			<17045 16982 16785 16544 16481 16462>,
			<17062 16953 16793 16551 16487 16465>,
			<17090 16932 16805 16560 16492 16469>,
			<17166 17015 16835 16570 16494 16475>,
			<17271 17165 16876 16582 16496 16482>,
			<17264 17187 16897 16600 16501 16487>,
			<17006 17056 16912 16630 16515 16489>,
			<16799 16921 16919 16659 16532 16493>,
			<16798 16857 16883 16678 16550 16504>,
			<16805 16810 16811 16693 16570 16523>,
			<16805 16784 16764 16696 16594 16547>,
			<16786 16769 16733 16689 16626 16585>,
			<16770 16755 16704 16676 16645 16607>,
			<16775 16733 16671 16631 16606 16579>,
			<16788 16705 16640 16556 16532 16523>,
			<16798 16670 16620 16522 16498 16492>,
			<16806 16614 16608 16510 16482 16473>,
			<16811 16575 16597 16505 16475 16465>,
			<16811 16580 16584 16506 16479 16468>,
			<16810 16595 16571 16512 16488 16476>,
			<16808 16606 16558 16518 16498 16485>,
			<16798 16611 16542 16525 16511 16497>,
			<16789 16617 16534 16533 16523 16510>,
			<16790 16635 16537 16541 16531 16527>,
			<16795 16670 16546 16548 16537 16544>,
			<16800 16694 16557 16551 16540 16548>,
			<16803 16707 16572 16551 16543 16544>,
			<16806 16717 16589 16551 16545 16537>,
			<16814 16728 16608 16548 16532 16517>,
			<16827 16739 16628 16543 16506 16489>,
			<16842 16742 16639 16541 16498 16482>,
			<16859 16740 16646 16542 16497 16483>,
			<16877 16735 16652 16542 16497 16484>,
			<16897 16722 16659 16544 16498 16485>,
			<16921 16701 16664 16546 16500 16487>,
			<16949 16698 16655 16541 16491 16473>,
			<16965 16699 16649 16531 16479 16461>,
			<16917 16709 16637 16531 16478 16460>,
			<16834 16700 16647 16526 16488 16474>,
			<16843 16722 16673 16548 16501 16498>,
			<16857 16749 16705 16571 16530 16529>,
			<16865 16771 16743 16590 16538 16532>,
			<16851 16766 16747 16572 16490 16474>,
			<16818 16725 16709 16546 16478 16465>,
			<16820 16713 16705 16562 16490 16474>,
			<16976 16723 16716 16602 16535 16519>,
			<16976 16723 16716 16602 16535 16519>,
			<16976 16723 16716 16602 16535 16519>;
	};

	qcom,pc-temp-y5-lut {
		qcom,lut-col-legend = <(-10) 0 10 25 40 50>;
		qcom,lut-row-legend = <10000 9800 9600 9400 9200 9000>,
			<8800 8600 8400 8200 8000 7800>,
			<7600 7400 7200 7000 6800 6600>,
			<6400 6200 6000 5800 5600 5400>,
			<5200 5000 4800 4600 4400 4200>,
			<4000 3800 3600 3400 3200 3000>,
			<2800 2600 2400 2200 2000 1800>,
			<1600 1400 1200 1000 900 800>,
			<700 600 500 400 300 200>,
			<100 0>;
		qcom,lut-data = <12959 11700 14772 17654 15369 16229>,
			<12746 12216 15027 17320 15762 16824>,
			<12919 13118 15294 16895 15989 17315>,
			<13407 14121 15549 16453 16090 17686>,
			<14135 14943 15764 16065 16104 17921>,
			<15032 15298 15914 15806 16071 18004>,
			<16491 15251 16018 15643 15959 17918>,
			<18041 15171 16090 15504 15751 17718>,
			<18062 15256 16089 15352 15468 17469>,
			<16030 15890 16003 14911 14997 17042>,
			<14511 16350 15861 14548 14723 16549>,
			<16062 16066 15316 14329 15069 15921>,
			<19017 15562 14556 14022 15646 15323>,
			<19909 16050 14796 13779 15633 15288>,
			<19782 20508 17392 13433 14743 15761>,
			<19617 24001 19842 13212 13994 16093>,
			<19540 22879 21020 13759 13799 15431>,
			<19407 20589 21851 15293 13723 14246>,
			<19429 20004 21940 17400 13935 13838>,
			<19901 20486 21627 21406 14980 13763>,
			<20318 21091 21380 24235 16363 13827>,
			<18916 21612 21309 23770 18207 15666>,
			<15530 22095 21225 22406 20130 18706>,
			<13617 22177 21159 21326 20298 19333>,
			<12685 21672 20973 20536 18500 18584>,
			<12206 20769 20914 19845 16894 17649>,
			<12192 18453 21971 19105 16452 16735>,
			<12202 14766 23744 18362 16177 15810>,
			<12237 13590 23604 18137 16091 15368>,
			<12497 13747 19487 18242 16149 15129>,
			<12746 13898 16317 18438 16290 14982>,
			<12744 13732 16383 18842 16931 14895>,
			<12693 13301 16673 19604 17907 14851>,
			<12648 13151 17000 20364 18098 15097>,
			<12619 13321 17473 21250 17759 16651>,
			<12585 13568 17974 21868 17471 17843>,
			<12501 13765 18459 21311 17375 17837>,
			<12361 13961 18894 19520 17261 17750>,
			<12292 14199 18990 18348 17126 17630>,
			<12277 14589 18897 17939 16790 17422>,
			<12269 14888 18702 17590 16441 17196>,
			<12350 14687 17204 16945 16168 16947>,
			<12580 14092 14919 16198 15874 16740>,
			<12769 13729 14094 16071 15556 17015>,
			<13068 13459 13832 16050 15593 17532>,
			<13508 13199 14123 15962 15703 17599>,
			<13727 13316 13849 16310 15402 16398>,
			<13959 13281 13773 15325 16086 16425>,
			<14108 13678 13817 15352 16525 16375>,
			<14332 14150 14149 15839 16881 15850>,
			<14422 14083 14084 16380 16362 16786>,
			<13781 13436 13889 17827 19112 18146>,
			<12860 13275 13836 18988 23194 20546>,
			<11717 13488 14163 20254 25290 25333>,
			<11717 13488 14163 20254 25290 25333>,
			<11717 13488 14163 20254 25290 25333>;
	};

	qcom,pc-temp-y6-lut {
		qcom,lut-col-legend = <(-10) 0 10 25 40 50>;
		qcom,lut-row-legend = <10000 9800 9600 9400 9200 9000>,
			<8800 8600 8400 8200 8000 7800>,
			<7600 7400 7200 7000 6800 6600>,
			<6400 6200 6000 5800 5600 5400>,
			<5200 5000 4800 4600 4400 4200>,
			<4000 3800 3600 3400 3200 3000>,
			<2800 2600 2400 2200 2000 1800>,
			<1600 1400 1200 1000 900 800>,
			<700 600 500 400 300 200>,
			<100 0>;
		qcom,lut-data = <6598 5954 5479 5151 5068 5053>,
			<6548 5958 5481 5151 5070 5053>,
			<6501 5956 5482 5151 5071 5053>,
			<6456 5950 5482 5152 5072 5054>,
			<6415 5940 5481 5153 5074 5055>,
			<6377 5929 5480 5154 5075 5056>,
			<6344 5913 5476 5155 5077 5057>,
			<6313 5894 5469 5156 5079 5059>,
			<6280 5878 5465 5158 5081 5061>,
			<6239 5860 5461 5160 5083 5063>,
			<6216 5850 5460 5163 5085 5065>,
			<6221 5850 5461 5166 5088 5068>,
			<6232 5851 5463 5169 5092 5070>,
			<6225 5848 5464 5172 5095 5073>,
			<6150 5823 5466 5176 5098 5076>,
			<6087 5793 5467 5181 5102 5080>,
			<6083 5771 5457 5188 5106 5083>,
			<6082 5751 5437 5195 5111 5087>,
			<6080 5738 5421 5197 5116 5091>,
			<6076 5730 5406 5196 5123 5097>,
			<6071 5722 5392 5193 5126 5101>,
			<6061 5713 5379 5179 5113 5091>,
			<6048 5704 5368 5151 5089 5072>,
			<6043 5695 5361 5139 5077 5062>,
			<6043 5685 5357 5135 5070 5055>,
			<6043 5679 5355 5133 5068 5052>,
			<6048 5681 5356 5133 5069 5053>,
			<6059 5687 5357 5135 5072 5056>,
			<6072 5696 5357 5137 5076 5059>,
			<6089 5713 5356 5141 5080 5063>,
			<6108 5735 5355 5144 5084 5067>,
			<6129 5758 5361 5148 5088 5072>,
			<6152 5784 5379 5151 5092 5076>,
			<6177 5813 5397 5155 5093 5078>,
			<6205 5844 5419 5158 5093 5078>,
			<6234 5877 5444 5160 5093 5078>,
			<6264 5913 5473 5160 5088 5072>,
			<6296 5950 5504 5160 5081 5062>,
			<6329 5988 5537 5160 5078 5060>,
			<6366 6026 5572 5164 5079 5061>,
			<6405 6063 5608 5169 5080 5063>,
			<6446 6094 5642 5175 5081 5064>,
			<6491 6123 5678 5182 5083 5065>,
			<6542 6158 5721 5188 5079 5060>,
			<6599 6202 5778 5195 5078 5058>,
			<6627 6238 5793 5203 5082 5064>,
			<6589 6234 5810 5199 5088 5069>,
			<6651 6283 5861 5212 5097 5079>,
			<6710 6337 5921 5229 5109 5091>,
			<6777 6389 5982 5244 5112 5090>,
			<6846 6431 6027 5244 5091 5070>,
			<6923 6476 6086 5246 5091 5068>,
			<7091 6569 6212 5283 5103 5076>,
			<7706 6716 6345 5332 5123 5096>,
			<7706 6716 6345 5332 5123 5096>,
			<7706 6716 6345 5332 5123 5096>;
	};

};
